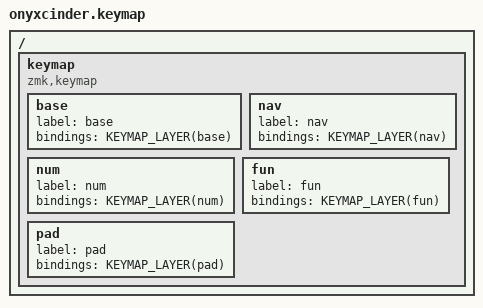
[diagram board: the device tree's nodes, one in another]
/*
 * Onyx Cinder (eggsworks "le oeuf") — thin keymap. Unibody 36-key on xiao_ble
 * (rows driven by a 595 shift register over SPI); vendored shield in
 * boards/shields/onyxcinder/. 3x5 core + 3 thumbs/hand, contiguous 0..35, so it reuses
 * the shared adapter geom_3x5_3.h (same as MNHTTN). All content lives in config/shared/.
 */

#include <behaviors.dtsi>
#include <dt-bindings/zmk/keys.h>
#include <dt-bindings/zmk/bt.h>
#include <dt-bindings/zmk/outputs.h>

#include "geometry/geom_3x5_3.h"

#include "shared/keys_de.h"
#include "shared/settings.dtsi"
#include "shared/behaviors.dtsi"
#include "shared/macros.dtsi"
#include "shared/combos.dtsi"
#include "shared/core_blocks.dtsi"

/ {
    keymap {
        compatible = "zmk,keymap";

        base { label = "base"; bindings = <KEYMAP_LAYER(base)>; };
        nav  { label = "nav";  bindings = <KEYMAP_LAYER(nav)>;  };
        num  { label = "num";  bindings = <KEYMAP_LAYER(num)>;  };
        fun  { label = "fun";  bindings = <KEYMAP_LAYER(fun)>;  };
        pad  { label = "pad";  bindings = <KEYMAP_LAYER(pad)>;  };
    };
};
